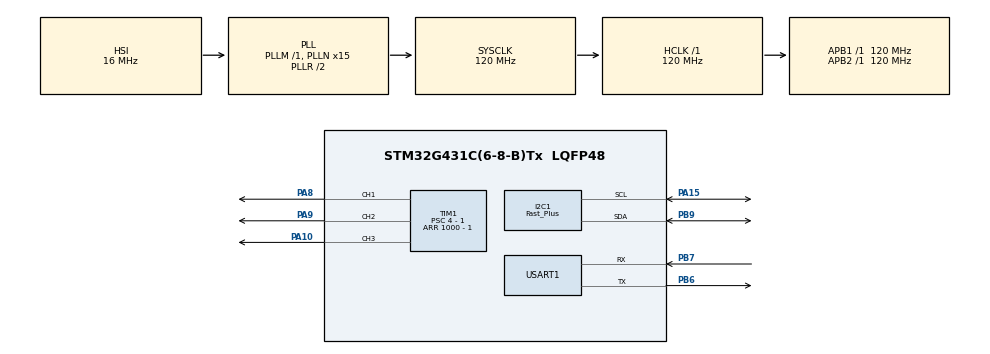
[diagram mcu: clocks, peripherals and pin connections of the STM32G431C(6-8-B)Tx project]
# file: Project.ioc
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Dma.Request0=USART1_RX
Dma.USART1_RX.0.Direction=DMA_PERIPH_TO_MEMORY
Dma.USART1_RX.0.EventEnable=DISABLE
Dma.USART1_RX.0.Instance=DMA1_Channel1
Dma.USART1_RX.0.MemDataAlignment=DMA_MDATAALIGN_BYTE
Dma.USART1_RX.0.MemInc=DMA_MINC_ENABLE
Dma.USART1_RX.0.Mode=DMA_CIRCULAR
Dma.USART1_RX.0.PeriphDataAlignment=DMA_PDATAALIGN_BYTE
Dma.USART1_RX.0.PeriphInc=DMA_PINC_DISABLE
Dma.USART1_RX.0.Polarity=HAL_DMAMUX_REQ_GEN_RISING
Dma.USART1_RX.0.Priority=DMA_PRIORITY_MEDIUM
Dma.USART1_RX.0.RequestNumber=1
Dma.USART1_RX.0.SignalID=NONE
Dma.USART1_RX.0.SyncEnable=DISABLE
Dma.USART1_RX.0.SyncPolarity=HAL_DMAMUX_SYNC_NO_EVENT
Dma.USART1_RX.0.SyncRequestNumber=1
Dma.USART1_RX.0.SyncSignalID=NONE
I2C1.I2C_Speed_Mode=I2C_Fast_Plus
I2C1.Timing=0x10820B1B
Mcu.Family=STM32G4
Mcu.Name=STM32G431C(6-8-B)Tx
Mcu.Package=LQFP48
NVIC.DMA1_Channel1_IRQn=true\:0\:0\:false\:false\:true\:false\:true\:true
NVIC.PriorityGroup=NVIC_PRIORITYGROUP_4
NVIC.USART1_IRQn=true\:0\:0\:false\:false\:true\:true\:true\:true
PA10.Signal=S_TIM1_CH3
PA13.Mode=Serial_Wire
PA13.Signal=SYS_JTMS-SWDIO
PA14.Mode=Serial_Wire
PA14.Signal=SYS_JTCK-SWCLK
PA15.Mode=I2C
PA15.Signal=I2C1_SCL
PA8.Signal=S_TIM1_CH1
PA9.Signal=S_TIM1_CH2
PB6.Mode=Asynchronous
PB6.Signal=USART1_TX
PB7.Mode=Asynchronous
PB7.Signal=USART1_RX
PB9.Mode=I2C
PB9.Signal=I2C1_SDA
ProjectManager.HeapSize=0x200
ProjectManager.StackSize=0x400
ProjectManager.TargetToolchain=MDK-ARM V5.32
RCC.ADC12Freq_Value=120000000
RCC.AHBFreq_Value=120000000
RCC.APB1Freq_Value=120000000
RCC.APB1TimFreq_Value=120000000
RCC.APB2Freq_Value=120000000
RCC.APB2TimFreq_Value=120000000
RCC.CortexFreq_Value=120000000
RCC.EXTERNAL_CLOCK_VALUE=12288000
RCC.HCLKFreq_Value=120000000
RCC.HSE_VALUE=8000000
RCC.HSI48_VALUE=48000000
RCC.HSI_VALUE=16000000
RCC.LSE_VALUE=32768
RCC.PLLN=15
RCC.SYSCLKFreq_VALUE=120000000
RCC.SYSCLKSource=RCC_SYSCLKSOURCE_PLLCLK
RCC.USBFreq_Value=120000000
RCC.VCOOutputFreq_Value=240000000
SH.S_TIM1_CH1.0=TIM1_CH1,PWM Generation1 CH1
SH.S_TIM1_CH2.0=TIM1_CH2,PWM Generation2 CH2
SH.S_TIM1_CH3.0=TIM1_CH3,PWM Generation3 CH3
TIM1.Channel-PWM\ Generation1\ CH1=TIM_CHANNEL_1
TIM1.Channel-PWM\ Generation2\ CH2=TIM_CHANNEL_2
TIM1.Channel-PWM\ Generation3\ CH3=TIM_CHANNEL_3
TIM1.PeriodNoDither=1000 - 1
TIM1.Prescaler=4 - 1
USART1.VirtualMode-Asynchronous=VM_ASYNC
VP_SYS_VS_DBSignals.Mode=DisableDeadBatterySignals
VP_TIM1_VS_ClockSourceINT.Mode=Internal
board=custom

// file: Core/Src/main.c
/* USER CODE BEGIN Header */
/**
  ******************************************************************************
  * @file           : main.c
  * @brief          : Main program body
  I2C通信与角度测量
  ******************************************************************************
  * @attention
  *
  * Copyright (c) 2026 STMicroelectronics.
  * All rights reserved.
  *
  * This software is licensed under terms that can be found in the LICENSE file
  * in the root directory of this software component.
  * If no LICENSE file comes with this software, it is provided AS-IS.
  *
  ******************************************************************************
  */
/* USER CODE END Header */
#include "main.h"
#include "dma.h"
#include "i2c.h"
#include "tim.h"
#include "usart.h"
#include "gpio.h"

/* USER CODE BEGIN Includes */
#include "Driver.h"
#include "Encoder.h"
#include "Serial.h"

/* USER CODE END Includes */

void SystemClock_Config(void);

/* USER CODE BEGIN 0 */
float currntAngle, totalAngle;
uint16_t raw_data;

//float Encoder_GetAngleNoTrack(void);
//float Encoder_GetAngle(void);
/* USER CODE END 0 */

int main(void)
{

  /* MCU Configuration--------------------------------------------------------*/

  /* Reset of all peripherals, Initializes the Flash interface and the Systick. */
  HAL_Init();

  /* Configure the system clock */
  SystemClock_Config();

  /* Initialize all configured peripherals */
  MX_GPIO_Init();
  MX_DMA_Init();
  MX_TIM1_Init();
  MX_I2C1_Init();
  MX_USART1_UART_Init();
  /* USER CODE BEGIN 2 */
  Serial_Init();   // 替代之前的 Serial_Init_DMA

  /* USER CODE END 2 */

  /* Infinite loop */
  /* USER CODE BEGIN WHILE */
  while (1)
  {
	  raw_data = Encoder_GetData(&hi2c1);
	  currntAngle = Encoder_GetAngleNoTrack();
	  totalAngle = Encoder_GetAngle();
	  VOFA_SendData(currntAngle, totalAngle, 0.0f, 0.0f);
	  HAL_Delay(10); // 简单的延时，控制读取频率
    /* USER CODE END WHILE */

  }
}

void SystemClock_Config(void)
{
  RCC_OscInitTypeDef RCC_OscInitStruct = {0};
  RCC_ClkInitTypeDef RCC_ClkInitStruct = {0};

  /** Configure the main internal regulator output voltage
  */
  HAL_PWREx_ControlVoltageScaling(PWR_REGULATOR_VOLTAGE_SCALE1);

  /** Initializes the RCC Oscillators according to the specified parameters
  * in the RCC_OscInitTypeDef structure.
  */
  RCC_OscInitStruct.OscillatorType = RCC_OSCILLATORTYPE_HSI;
  RCC_OscInitStruct.HSIState = RCC_HSI_ON;
  RCC_OscInitStruct.HSICalibrationValue = RCC_HSICALIBRATION_DEFAULT;
  RCC_OscInitStruct.PLL.PLLState = RCC_PLL_ON;
  RCC_OscInitStruct.PLL.PLLSource = RCC_PLLSOURCE_HSI;
  RCC_OscInitStruct.PLL.PLLM = RCC_PLLM_DIV1;
  RCC_OscInitStruct.PLL.PLLN = 15;
  RCC_OscInitStruct.PLL.PLLP = RCC_PLLP_DIV2;
  RCC_OscInitStruct.PLL.PLLQ = RCC_PLLQ_DIV2;
  RCC_OscInitStruct.PLL.PLLR = RCC_PLLR_DIV2;
  if (HAL_RCC_OscConfig(&RCC_OscInitStruct) != HAL_OK)
  {
    Error_Handler();
  }

  /** Initializes the CPU, AHB and APB buses clocks
  */
  RCC_ClkInitStruct.ClockType = RCC_CLOCKTYPE_HCLK|RCC_CLOCKTYPE_SYSCLK
                              |RCC_CLOCKTYPE_PCLK1|RCC_CLOCKTYPE_PCLK2;
  RCC_ClkInitStruct.SYSCLKSource = RCC_SYSCLKSOURCE_PLLCLK;
  RCC_ClkInitStruct.AHBCLKDivider = RCC_SYSCLK_DIV1;
  RCC_ClkInitStruct.APB1CLKDivider = RCC_HCLK_DIV1;
  RCC_ClkInitStruct.APB2CLKDivider = RCC_HCLK_DIV1;

  if (HAL_RCC_ClockConfig(&RCC_ClkInitStruct, FLASH_LATENCY_3) != HAL_OK)
  {
    Error_Handler();
  }
}

void Error_Handler(void)
{
  __disable_irq();
  while (1)
  {
  }
}
